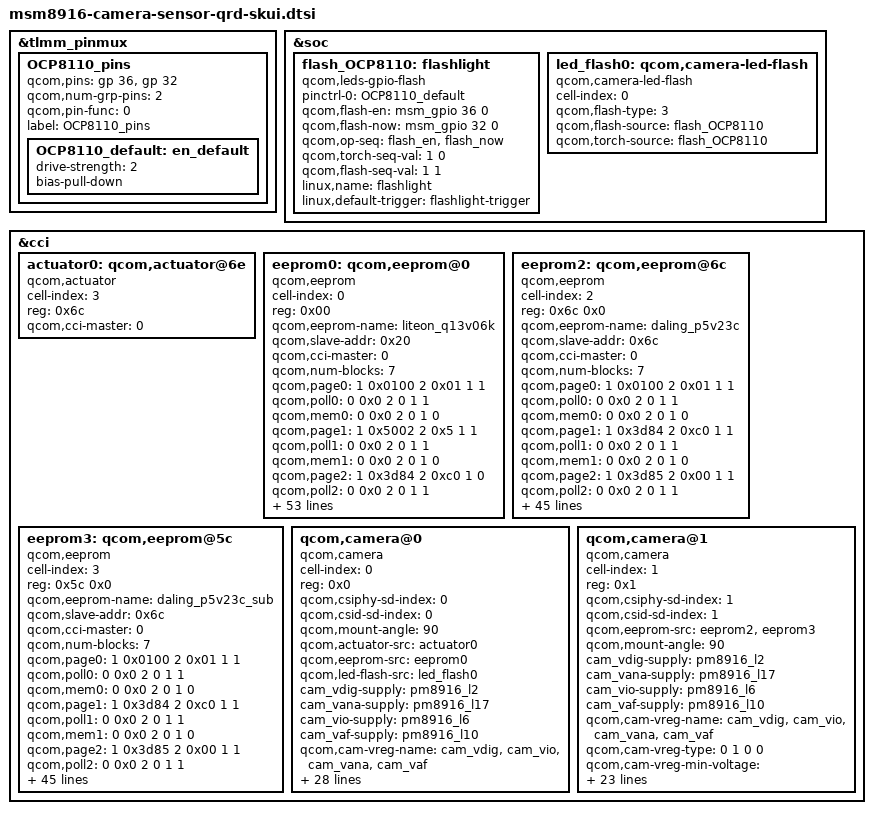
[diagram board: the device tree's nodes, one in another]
/*
 * Copyright (c) 2014, The Linux Foundation. All rights reserved.
 *
 * This program is free software; you can redistribute it and/or modify
 * it under the terms of the GNU General Public License version 2 and
 * only version 2 as published by the Free Software Foundation.
 *
 * This program is distributed in the hope that it will be useful,
 * but WITHOUT ANY WARRANTY; without even the implied warranty of
 * MERCHANTABILITY or FITNESS FOR A PARTICULAR PURPOSE.  See the
 * GNU General Public License for more details.
 */

&tlmm_pinmux {
	OCP8110_pins {
		qcom,pins = <&gp 36>, <&gp 32>;
		qcom,num-grp-pins = <2>;
		qcom,pin-func = <0>;
		label = "OCP8110_pins";
		OCP8110_default: en_default {
			  drive-strength = <2>;
			  bias-pull-down;
		};
	};
};

&soc {
	flash_OCP8110:flashlight {
		compatible = "qcom,leds-gpio-flash";
		status = "okay";
		pinctrl-names = "flash_default";
		pinctrl-0 = <&OCP8110_default>;
		qcom,flash-en = <&msm_gpio 36 0>;
		qcom,flash-now = <&msm_gpio 32 0>;
		qcom,op-seq = "flash_en", "flash_now";
		qcom,torch-seq-val = <1 0>;
		qcom,flash-seq-val = <1 1>;
		linux,name = "flashlight";
		linux,default-trigger = "flashlight-trigger";
	};

	led_flash0: qcom,camera-led-flash {
		cell-index = <0>;
		compatible = "qcom,camera-led-flash";
		qcom,flash-type = <3>;
		qcom,flash-source = <&flash_OCP8110>;
		qcom,torch-source = <&flash_OCP8110>;
	};
};

&cci {

	actuator0: qcom,actuator@6e {
		cell-index = <3>;
		reg = <0x6c>;
		compatible = "qcom,actuator";
		qcom,cci-master = <0>;
	};
//Begin<REQ><JABAL-1500><20150804>Add camera for L5261;xiongdajun
	/*eeprom0: qcom,eeprom@6b{
		cell-index = <0>;
		reg = <0x6b>;
		qcom,eeprom-name = "sunny_q5v22e";
		compatible = "qcom,eeprom";
		qcom,slave-addr = <0x6c>;
		qcom,cci-master = <0>;
		qcom,num-blocks = <7>;

		qcom,page0 = <1 0x0100 2 0x01 1 1>;
		qcom,poll0 = <0 0x0 2 0 1 1>;
		qcom,mem0 = <0 0x0 2 0 1 0>;
		qcom,page1 = <1 0x3d84 2 0xc0 1 1>;
		qcom,poll1 = <0 0x0 2 0 1 1>;
		qcom,mem1 = <0 0x0 2 0 1 0>;
		qcom,page2 = <1 0x3d85 2 0x00 1 1>;
		qcom,poll2 = <0 0x0 2 0 1 1>;
		qcom,mem2 = <0 0x0 2 0 1 0>;
		qcom,page3 = <1 0x3d86 2 0x0f 1 1>;
		qcom,pageen3 = <1 0x3d81 2 0x01 1 10>;
		qcom,poll3 = <0 0x0 2 0 1 1>;
		qcom,mem3 = <16 0x3d00 2 0 1 0>;
		qcom,page4 = <1 0x3d84 2 0xc0 1 1>;
		qcom,poll4 = <0 0x0 2 0 1 1>;
		qcom,mem4 = <0 0x0 2 0 1 0>;
		qcom,page5 = <1 0x3d85 2 0x10 1 1>;
		qcom,poll5 = <0 0x0 2 0 1 1>;
		qcom,mem5 = <0 0x0 2 0 1 0>;
		qcom,page6 = <1 0x3d86 2 0x1f 1 1>;
		qcom,pageen6 = <1 0x3d81 2 0x01 1 10>;
		qcom,poll6 = <0 0x0 2 0 1 1>;
		qcom,mem6 = <16 0x3d00 2 0 1 0>;

		cam_vdig-supply = <&pm8916_l2>;
		cam_vana-supply = <&pm8916_l17>;
		cam_vio-supply = <&pm8916_l6>;
		cam_vaf-supply = <&pm8916_l10>;
		qcom,cam-vreg-name = "cam_vdig", "cam_vio", "cam_vana",
							"cam_vaf";
		qcom,cam-vreg-min-voltage = <2100000 0 2850000 2800000>;
		qcom,cam-vreg-max-voltage = <2100000 0 2850000 2800000>;
		qcom,cam-vreg-op-mode = <200000 0 80000 100000>;
		pinctrl-names = "cam_default", "cam_suspend";
		pinctrl-0 = <&cam_sensor_mclk0_default &cam_sensor_rear_default>;
		pinctrl-1 = <&cam_sensor_mclk0_sleep &cam_sensor_rear_sleep>;
		gpios = <&msm_gpio 26 0>,
			<&msm_gpio 35 0>,
			<&msm_gpio 34 0>;
		qcom,gpio-reset = <1>;
		qcom,gpio-standby = <2>;
		qcom,gpio-req-tbl-num = <0 1 2 >;
		qcom,gpio-req-tbl-flags = <1 0 0>;
		qcom,gpio-req-tbl-label = "CAMIF_MCLK",
			"CAM_RESET1",
			"CAM_STANDBY";

		qcom,cam-power-seq-type = "sensor_vreg",
			"sensor_gpio", "sensor_gpio",
			"sensor_clk";
		qcom,cam-power-seq-val = "cam_vaf",
			"sensor_gpio_reset",
			"sensor_gpio_standby",
			"sensor_cam_mclk" ;
		qcom,cam-power-seq-cfg-val = <1 1 1 23880000>;
		qcom,cam-power-seq-delay = <1 10 10 5>;

		clocks = <&clock_gcc clk_mclk0_clk_src>,
			<&clock_gcc clk_gcc_camss_mclk0_clk>;
		clock-names = "cam_src_clk", "cam_clk";
	};


	qcom,camera@42 {
		compatible = "ovti,ov7695";
		reg = <0x42 0x0>;
		qcom,slave-id = <0x42 0x300a 0x7695>;
		qcom,csiphy-sd-index = <1>;
		qcom,csid-sd-index = <1>;
		qcom,mount-angle = <90>;
		qcom,sensor-name = "ov7695";
		cam_vdig-supply = <&pm8916_l2>;
		cam_vana-supply = <&pm8916_l17>;
		cam_vio-supply = <&pm8916_l6>;
		cam_vaf-supply = <&pm8916_l10>;
		qcom,cam-vreg-name = "cam_vdig", "cam_vio", "cam_vana",
							"cam_vaf";
		qcom,cam-vreg-type = <0 1 0 0>;
		qcom,cam-vreg-min-voltage = <1200000 0 2850000 2800000>;
		qcom,cam-vreg-max-voltage = <1200000 0 2850000 2800000>;
		qcom,cam-vreg-op-mode = <200000 0 80000 100000>;
		pinctrl-names = "cam_default", "cam_suspend";
		pinctrl-0 = <&cam_sensor_mclk1_default &cam_sensor_front_default>;
		pinctrl-1 = <&cam_sensor_mclk1_sleep &cam_sensor_front_sleep>;
		gpios = <&msm_gpio 27 0>,
			<&msm_gpio 28 0>,
			<&msm_gpio 33 0>;
		qcom,gpio-reset = <1>;
		qcom,gpio-standby = <2>;
		qcom,gpio-req-tbl-num = <0 1 2>;
		qcom,gpio-req-tbl-flags = <1 0 0>;
		qcom,gpio-req-tbl-label = "CAMIF_MCLK",
					"CAM_RESET",
					"CAM_STANDBY";
		qcom,csi-lane-assign = <0x4320>;
		qcom,csi-lane-mask = <0x3>;
		qcom,sensor-position = <1>;
		qcom,sensor-mode = <0>;
		qcom,cci-master = <0>;
		qcom,mclk-23880000;
		status = "ok";
		clocks = <&clock_gcc clk_mclk1_clk_src>,
				<&clock_gcc clk_gcc_camss_mclk1_clk>;
		clock-names = "cam_src_clk", "cam_clk";
	};

	qcom,camera@0 {
		cell-index = <0>;
		compatible = "qcom,camera";
		reg = <0x0>;
		qcom,csiphy-sd-index = <0>;
		qcom,csid-sd-index = <0>;
		qcom,mount-angle = <90>;
		qcom,actuator-src = <&actuator0>;
		qcom,eeprom-src = <&eeprom0>;
		qcom,led-flash-src = <&led_flash0>;
		cam_vdig-supply = <&pm8916_l2>;
		cam_vana-supply = <&pm8916_l17>;
		cam_vio-supply = <&pm8916_l6>;
		cam_vaf-supply = <&pm8916_l10>;
		qcom,cam-vreg-name = "cam_vdig", "cam_vio", "cam_vana",
							"cam_vaf";
		qcom,cam-vreg-min-voltage = <1200000 0 2850000 2800000>;
		qcom,cam-vreg-max-voltage = <1200000 0 2850000 2800000>;
		qcom,cam-vreg-op-mode = <200000 0 80000 100000>;
		pinctrl-names = "cam_default", "cam_suspend";
		pinctrl-0 = <&cam_sensor_mclk0_default &cam_sensor_rear_default>;
		pinctrl-1 = <&cam_sensor_mclk0_sleep &cam_sensor_rear_sleep>;
		gpios = <&msm_gpio 26 0>,
			<&msm_gpio 35 0>,
			<&msm_gpio 34 0>,
			<&msm_gpio 120 0>;
		qcom,gpio-reset = <1>;
		qcom,gpio-standby = <2>;
		qcom,gpio-af-pwdm = <3>;
		qcom,gpio-req-tbl-num = <0 1 2 3>;
		qcom,gpio-req-tbl-flags = <1 0 0 0>;
		qcom,gpio-req-tbl-label = "CAMIF_MCLK",
			"CAM_RESET1",
			"CAM_STANDBY",
			"CAM_AF_PWDM";
		qcom,sensor-position = <0>;
		qcom,sensor-mode = <0>;
		qcom,cci-master = <0>;
		qcom,mclk-23880000;
		status = "ok";
		clocks = <&clock_gcc clk_mclk0_clk_src>,
				<&clock_gcc clk_gcc_camss_mclk0_clk>;
		clock-names = "cam_src_clk", "cam_clk";
	};

	qcom,camera@1 {
		cell-index = <1>;
		compatible = "qcom,camera";
		reg = <0x1>;
		qcom,csiphy-sd-index = <1>;
		qcom,csid-sd-index = <1>;
		qcom,mount-angle = <90>;
		cam_vdig-supply = <&pm8916_l2>;
		cam_vana-supply = <&pm8916_l17>;
		cam_vio-supply = <&pm8916_l6>;
		cam_vaf-supply = <&pm8916_l10>;
		qcom,cam-vreg-name = "cam_vdig", "cam_vio", "cam_vana",
							"cam_vaf";
		qcom,cam-vreg-min-voltage = <1200000 0 2850000 2800000>;
		qcom,cam-vreg-max-voltage = <1200000 0 2850000 2800000>;
		qcom,cam-vreg-op-mode = <200000 0 80000 100000>;
		pinctrl-names = "cam_default", "cam_suspend";
		pinctrl-0 = <&cam_sensor_mclk1_default &cam_sensor_front_default>;
		pinctrl-1 = <&cam_sensor_mclk1_sleep &cam_sensor_front_sleep>;
		gpios = <&msm_gpio 27 0>,
			<&msm_gpio 28 0>,
			<&msm_gpio 33 0>;
		qcom,gpio-reset = <1>;
		qcom,gpio-standby = <2>;
		qcom,gpio-req-tbl-num = <0 1 2>;
		qcom,gpio-req-tbl-flags = <1 0 0>;
		qcom,gpio-req-tbl-label = "CAMIF_MCLK",
			"CAM_RESET",
			"CAM_STANDBY";
		qcom,sensor-position = <1>;
		qcom,sensor-mode = <0>;
		qcom,cci-master = <0>;
		qcom,mclk-23880000;
		status = "ok";
		clocks = <&clock_gcc clk_mclk1_clk_src>,
				<&clock_gcc clk_gcc_camss_mclk1_clk>;
		clock-names = "cam_src_clk", "cam_clk";
	};*/
			
    eeprom0: qcom,eeprom@0{
                cell-index = <0>;
                reg = <0x00>;
                qcom,eeprom-name = "liteon_q13v06k";
                compatible = "qcom,eeprom";
                qcom,slave-addr = <0x20>;
                qcom,cci-master = <0>;
                qcom,num-blocks = <7>;
                
		qcom,page0 = <1 0x0100 2 0x01 1 1>;
		qcom,poll0 = <0 0x0 2 0 1 1>;
		qcom,mem0 = <0 0x0 2 0 1 0>;
		qcom,page1 = <1 0x5002 2 0x5 1 1>;
		qcom,poll1 = <0 0x0 2 0 1 1>;
		qcom,mem1 = <0 0x0 2 0 1 0>;
		qcom,page2 = <1 0x3d84 2 0xc0 1 0>;
		qcom,poll2 = <0 0x0 2 0 1 1>;
		qcom,mem2 = <0 0x0 2 0 1 0>;
		qcom,page3 = <1 0x3d88 2 0x7220 2 0>;
		qcom,poll3 = <0 0x0 2 0 1 1>;
		qcom,mem3 = <0 0x0 2 0 1 0>;
		qcom,page4 = <1 0x3d8a 2 0x73BA 2 0>;
		qcom,poll4 = <0 0x0 2 0 1 1>;
		qcom,mem4 = <0 0x0 2 0 1 0>;
		qcom,page5 = <1 0x3d81 2 0x01 1 15>;
		qcom,poll5 = <0 0x0 2 0 1 1>;
		qcom,mem5 = <411 0x7220 2 0 1 0>;
		qcom,page6 = <1 0x5002 2 0x7 1 1>;
		qcom,poll6 = <0 0x0 2 0 1 1>;
		qcom,mem6 = <0 0x0 2 0 1 0>;
        
         /*       qcom,page0 = <1 0x0100 2 0x01 1 1>;
                qcom,poll0 = <0 0x0 2 0 1 1>;
                qcom,mem0 = <0 0x0 2 0 1 0>;
                qcom,page1 = <1 0x5002 2 0x1 1 1>;
                qcom,poll1 = <0 0x0 2 0 1 1>;
                qcom,mem1 = <0 0x0 2 0 1 0>;
                qcom,page2 = <1 0x3d84 2 0xc0 1 0>;
                qcom,poll2 = <0 0x0 2 0 1 1>;
                qcom,mem2 = <0 0x0 2 0 1 0>;
                qcom,page3 = <1 0x3d88 2 0x7220 2 0>;
                qcom,poll3 = <0 0x0 2 0 1 1>;
                qcom,mem3 = <0 0x0 2 0 1 0>;
                qcom,page4 = <1 0x3d8a 2 0x7369 2 0>;
                qcom,poll4 = <0 0x0 2 0 1 1>;
                qcom,mem4 = <0 0x0 2 0 1 0>;
                qcom,page5 = <1 0x3d81 2 0x01 1 15>;
                qcom,poll5 = <0 0x0 2 0 1 1>;
                qcom,mem5 = <403 0x7220 2 0 1 0>;
                qcom,page6 = <1 0x5002 2 0x3 1 1>;
                qcom,poll6 = <0 0x0 2 0 1 1>;
                qcom,mem6 = <0 0x0 2 0 1 0>;*/
		cam_vdig-supply = <&pm8916_l2>;
		cam_vana-supply = <&pm8916_l17>;
		cam_vio-supply = <&pm8916_l6>;
		cam_vaf-supply = <&pm8916_l10>;
		qcom,cam-vreg-name = "cam_vdig", "cam_vana", "cam_vio",	"cam_vaf";
		qcom,cam-vreg-type = <0 1 0 0>;
		qcom,cam-vreg-min-voltage = <1200000 0 1800000 2800000>;
		qcom,cam-vreg-max-voltage = <1200000 0 1800000 2800000>;
		qcom,cam-vreg-op-mode = <200000 0 80000 100000>;
		pinctrl-names = "cam_default", "cam_suspend";
		pinctrl-0 = <&cam_sensor_mclk0_default &cam_sensor_rear_default>;
		pinctrl-1 = <&cam_sensor_mclk0_sleep &cam_sensor_rear_sleep>;
		gpios = <&msm_gpio 26 0>,
			<&msm_gpio 35 0>,
			<&msm_gpio 34 0>,
			<&msm_gpio 121 0>,//gpio_m
			<&msm_gpio 17 0>,
			<&msm_gpio 119 0>;
		qcom,gpio-reset = <1>;
		qcom,gpio-standby = <2>;
		qcom,gpio-af-pwdm = <3>;
		qcom,gpio-vdig = <4>;
		qcom,gpio-vana = <5>;
		qcom,gpio-req-tbl-num = <0 1 2 3 4 5>;
		qcom,gpio-req-tbl-flags = <1 0 0 0 0 0>;
		qcom,gpio-req-tbl-label = "CAMIF_MCLK",
			"CAM_RESET1",
			"CAM_STANDBY",
			"CAM_AF_PWDM",
			"CAM_VDIG",
			"CAM_VANA";

		qcom,cam-power-seq-type = "sensor_gpio", "sensor_gpio","sensor_vreg",  
			"sensor_vreg",
			"sensor_gpio", 
			"sensor_gpio",
			"sensor_clk";			
		qcom,cam-power-seq-val = "sensor_gpio_vdig", "sensor_gpio_vana", "cam_vio", 
			"cam_vaf",
			"sensor_gpio_reset",
			"sensor_gpio_standby",
			"sensor_cam_mclk";
		
		qcom,cam-power-seq-cfg-val = <1 1 1 1 1 1 23880000>;
		qcom,cam-power-seq-delay   = <5 5 5 1 10 10 5>;

		clocks = <&clock_gcc clk_mclk0_clk_src>,
			<&clock_gcc clk_gcc_camss_mclk0_clk>;
		clock-names = "cam_src_clk", "cam_clk";
	};
	// OV5648
        eeprom2: qcom,eeprom@6c{
                cell-index = <2>;
                reg = <0x6c 0x0>;
                qcom,eeprom-name = "daling_p5v23c";
                compatible = "qcom,eeprom";
                qcom,slave-addr = <0x6c>;
                qcom,cci-master = <0>;
                qcom,num-blocks = <7>;
    
                qcom,page0 = <1 0x0100 2 0x01 1 1>; 
                qcom,poll0 = <0 0x0 2 0 1 1>; 
                qcom,mem0 = <0 0x0 2 0 1 0>; 

                qcom,page1 = <1 0x3d84 2 0xc0 1 1>; 
                qcom,poll1 = <0 0x0 2 0 1 1>; 
                qcom,mem1 = <0 0x0 2 0 1 0>; 
            
                qcom,page2 = <1 0x3d85 2 0x00 1 1>; 
                qcom,poll2 = <0 0x0 2 0 1 1>; 
                qcom,mem2 = <0 0x0 2 0 1 0>; 
            
                qcom,page3 = <1 0x3d86 2 0x0f 1 1>; 
                qcom,pageen3 = <1 0x3d81 2 0x01 1 10>;
                qcom,poll3 = <0 0x0 2 0 1 1>; 
                qcom,mem3 = <16 0x3d00 2 0 1 0>;

                qcom,page4 = <1 0x3d84 2 0xc0 1 1>;
                qcom,poll4 = <0 0x0 2 0 1 1>;
                qcom,mem4 = <0 0x0 2 0 1 0>;
            
                qcom,page5 = <1 0x3d85 2 0x10 1 1>;
                qcom,poll5 = <0 0x0 2 0 1 1>;
                qcom,mem5 = <0 0x0 2 0 1 0>;
            
                qcom,page6 = <1 0x3d86 2 0x1f 1 1>;
                qcom,pageen6 = <1 0x3d81 2 0x01 1 10>;
                qcom,poll6 = <0 0x0 2 0 1 1>;
                qcom,mem6 = <16 0x3d00 2 0 1 0>;

		cam_vana-supply = <&pm8916_l17>;
		cam_vio-supply = <&pm8916_l6>;
		qcom,cam-vreg-name = "cam_vana", "cam_vio"; // Jiangde
		qcom,cam-vreg-type = <1 0>;
		qcom,cam-vreg-min-voltage = <0 2850000>;
		qcom,cam-vreg-max-voltage = <0 2850000>;
		qcom,cam-vreg-op-mode = <0 80000>;
		pinctrl-names = "cam_default", "cam_suspend";
		pinctrl-0 = <&cam_sensor_mclk1_default &cam_sensor_front_default>;
		pinctrl-1 = <&cam_sensor_mclk1_sleep &cam_sensor_front_sleep>;
		gpios = <&msm_gpio 27 0>,
			<&msm_gpio 28 0>,
			<&msm_gpio 33 0>,
			<&msm_gpio 119 0>; // Jiangde
		qcom,gpio-reset = <1>;
		qcom,gpio-standby = <2>;
		qcom,gpio-vana = <3>; // Jiangde
		qcom,gpio-req-tbl-num = <0 1 2 3>;   // Jiangde
		qcom,gpio-req-tbl-flags = <1 0 0 0>; // Jiangde
		qcom,gpio-req-tbl-label = "CAMIF_MCLK",
			"CAM_RESET",
			"CAM_STANDBY",
			"CAM_VANA"; // Jiangde
                
		qcom,cam-power-seq-type = "sensor_vreg", 
			"sensor_gpio", // Jiangde
			"sensor_gpio",
			"sensor_gpio",
			"sensor_clk";
		qcom,cam-power-seq-val = "cam_vio", 
			"sensor_gpio_vana", // Jiangde
			"sensor_gpio_standby",
			"sensor_gpio_reset",
			"sensor_cam_mclk" ;
		qcom,cam-power-seq-cfg-val = <1 1 1 1 23880000>;
		qcom,cam-power-seq-delay = <1 1 10 10 5>;

		clocks = <&clock_gcc clk_mclk1_clk_src>,<&clock_gcc clk_gcc_camss_mclk1_clk>;
		clock-names = "cam_src_clk", "cam_clk";
	};
//Begin<><><20141023>add daling sub bom otp;xiongdajun
    eeprom3: qcom,eeprom@5c{
                cell-index = <3>;
                reg = <0x5c 0x0>;
                qcom,eeprom-name = "daling_p5v23c_sub";
                compatible = "qcom,eeprom";
                qcom,slave-addr = <0x6c>;
                qcom,cci-master = <0>;
                qcom,num-blocks = <7>;
    
                qcom,page0 = <1 0x0100 2 0x01 1 1>; 
                qcom,poll0 = <0 0x0 2 0 1 1>; 
                qcom,mem0 = <0 0x0 2 0 1 0>; 

                qcom,page1 = <1 0x3d84 2 0xc0 1 1>; 
                qcom,poll1 = <0 0x0 2 0 1 1>; 
                qcom,mem1 = <0 0x0 2 0 1 0>; 
            
                qcom,page2 = <1 0x3d85 2 0x00 1 1>; 
                qcom,poll2 = <0 0x0 2 0 1 1>; 
                qcom,mem2 = <0 0x0 2 0 1 0>; 
            
                qcom,page3 = <1 0x3d86 2 0x0f 1 1>; 
                qcom,pageen3 = <1 0x3d81 2 0x01 1 10>;
                qcom,poll3 = <0 0x0 2 0 1 1>; 
                qcom,mem3 = <16 0x3d00 2 0 1 0>;

                qcom,page4 = <1 0x3d84 2 0xc0 1 1>;
                qcom,poll4 = <0 0x0 2 0 1 1>;
                qcom,mem4 = <0 0x0 2 0 1 0>;
            
                qcom,page5 = <1 0x3d85 2 0x10 1 1>;
                qcom,poll5 = <0 0x0 2 0 1 1>;
                qcom,mem5 = <0 0x0 2 0 1 0>;
            
                qcom,page6 = <1 0x3d86 2 0x1f 1 1>;
                qcom,pageen6 = <1 0x3d81 2 0x01 1 10>;
                qcom,poll6 = <0 0x0 2 0 1 1>;
                qcom,mem6 = <16 0x3d00 2 0 1 0>;

		cam_vana-supply = <&pm8916_l17>;
		cam_vio-supply = <&pm8916_l6>;
		qcom,cam-vreg-name = "cam_vana", "cam_vio"; // Jiangde
		qcom,cam-vreg-type = <1 0>;
		qcom,cam-vreg-min-voltage = <0 2850000>;
		qcom,cam-vreg-max-voltage = <0 2850000>;
		qcom,cam-vreg-op-mode = <0 80000>;
		pinctrl-names = "cam_default", "cam_suspend";
		pinctrl-0 = <&cam_sensor_mclk1_default &cam_sensor_front_default>;
		pinctrl-1 = <&cam_sensor_mclk1_sleep &cam_sensor_front_sleep>;
		gpios = <&msm_gpio 27 0>,
			<&msm_gpio 28 0>,
			<&msm_gpio 33 0>,
			<&msm_gpio 119 0>; // Jiangde
		qcom,gpio-reset = <1>;
		qcom,gpio-standby = <2>;
		qcom,gpio-vana = <3>; // Jiangde
		qcom,gpio-req-tbl-num = <0 1 2 3>;   // Jiangde
		qcom,gpio-req-tbl-flags = <1 0 0 0>; // Jiangde
		qcom,gpio-req-tbl-label = "CAMIF_MCLK",
			"CAM_RESET",
			"CAM_STANDBY",
			"CAM_VANA"; // Jiangde
                
		qcom,cam-power-seq-type = "sensor_vreg", 
			"sensor_gpio", // Jiangde
			"sensor_gpio",
			"sensor_gpio",
			"sensor_clk";
		qcom,cam-power-seq-val = "cam_vio", 
			"sensor_gpio_vana", // Jiangde
			"sensor_gpio_standby",
			"sensor_gpio_reset",
			"sensor_cam_mclk" ;
		qcom,cam-power-seq-cfg-val = <1 1 1 1 23880000>;
		qcom,cam-power-seq-delay = <1 1 10 10 5>;

		clocks = <&clock_gcc clk_mclk1_clk_src>,<&clock_gcc clk_gcc_camss_mclk1_clk>;
		clock-names = "cam_src_clk", "cam_clk";
	};
//END<><><20141023>add daling sub bom otp;xiongdajun
	qcom,camera@0 {
		cell-index = <0>;
		compatible = "qcom,camera";
		reg = <0x0>;
		qcom,csiphy-sd-index = <0>;
		qcom,csid-sd-index = <0>;
		qcom,mount-angle = <90>;
		qcom,actuator-src = <&actuator0>;
		qcom,eeprom-src = <&eeprom0>;
		qcom,led-flash-src = <&led_flash0>;
		cam_vdig-supply = <&pm8916_l2>;
		cam_vana-supply = <&pm8916_l17>;
		cam_vio-supply = <&pm8916_l6>;
		cam_vaf-supply = <&pm8916_l10>;
		qcom,cam-vreg-name = "cam_vdig", "cam_vio", "cam_vana",
							"cam_vaf";
		qcom,cam-vreg-type = <0 1 0 0>;
		qcom,cam-vreg-min-voltage = <1200000 0 2850000 2800000>;
		qcom,cam-vreg-max-voltage = <1200000 0 2850000 2800000>;
		qcom,cam-vreg-op-mode = <200000 0 80000 100000>;
		pinctrl-names = "cam_default", "cam_suspend";
		pinctrl-0 = <&cam_sensor_mclk0_default &cam_sensor_rear_default>;
		pinctrl-1 = <&cam_sensor_mclk0_sleep &cam_sensor_rear_sleep>;
		gpios = <&msm_gpio 26 0>,
			<&msm_gpio 35 0>,
			<&msm_gpio 34 0>,
			<&msm_gpio 121 0>,//gpio_m
			<&msm_gpio 17 0>,
			<&msm_gpio 119 0>;
		qcom,gpio-reset = <1>;
		qcom,gpio-standby = <2>;
		qcom,gpio-af-pwdm = <3>;
                qcom,gpio-vdig = <4>;
                qcom,gpio-vana = <5>;
		qcom,gpio-req-tbl-num = <0 1 2 3 4 5>;
		qcom,gpio-req-tbl-flags = <1 0 0 0 0 0>;
		qcom,gpio-req-tbl-label = "CAMIF_MCLK",
			"CAM_RESET1",
			"CAM_STANDBY",
			"CAM_AF_PWDM",
            "CAM_VDIG",
            "CAM_VANA";
		qcom,sensor-position = <0>;
		qcom,sensor-mode = <0>;
		qcom,cci-master = <0>;
		qcom,mclk-23880000;
		status = "ok";
		clocks = <&clock_gcc clk_mclk0_clk_src>,
				<&clock_gcc clk_gcc_camss_mclk0_clk>;
		clock-names = "cam_src_clk", "cam_clk";
	};

	qcom,camera@1 {
		cell-index = <1>;
		compatible = "qcom,camera";
		reg = <0x1>;
		qcom,csiphy-sd-index = <1>;
		qcom,csid-sd-index = <1>;
		qcom,eeprom-src = <&eeprom2 &eeprom3>;
		qcom,mount-angle = <90>;
		cam_vdig-supply = <&pm8916_l2>;
		cam_vana-supply = <&pm8916_l17>;
		cam_vio-supply = <&pm8916_l6>;
		cam_vaf-supply = <&pm8916_l10>;
		qcom,cam-vreg-name = "cam_vdig", "cam_vio", "cam_vana",
							"cam_vaf";
		qcom,cam-vreg-type = <0 1 0 0>;
		qcom,cam-vreg-min-voltage = <1500000 0 2850000 2800000>;
		qcom,cam-vreg-max-voltage = <1500000 0 2850000 2800000>;
		qcom,cam-vreg-op-mode = <200000 0 80000 100000>;
		pinctrl-names = "cam_default", "cam_suspend";
		pinctrl-0 = <&cam_sensor_mclk1_default &cam_sensor_front_default>;
		pinctrl-1 = <&cam_sensor_mclk1_sleep &cam_sensor_front_sleep>;
		gpios = <&msm_gpio 27 0>,
			<&msm_gpio 28 0>,
			<&msm_gpio 33 0>,
			<&msm_gpio 119 0>;
		qcom,gpio-reset = <1>;
		qcom,gpio-standby = <2>;
		qcom,gpio-vdig = <3>;
		qcom,gpio-req-tbl-num = <0 1 2 3>;
		qcom,gpio-req-tbl-flags = <1 0 0 0>;
		qcom,gpio-req-tbl-label = "CAMIF_MCLK",
			"CAM_RESET",
			"CAM_STANDBY",
			"CAM_VDIG";
		qcom,sensor-position = <1>;
		qcom,sensor-mode = <0>;
		qcom,cci-master = <0>;
		qcom,mclk-23880000;
		status = "ok";
		clocks = <&clock_gcc clk_mclk1_clk_src>,
				<&clock_gcc clk_gcc_camss_mclk1_clk>;
		clock-names = "cam_src_clk", "cam_clk";
	};
//END<REQ><JABAL-1500><20150804>Add camera for L5261;xiongdajun
};

